AUTOSAR XML (schema 4-0-3)
package /ComponentTypes
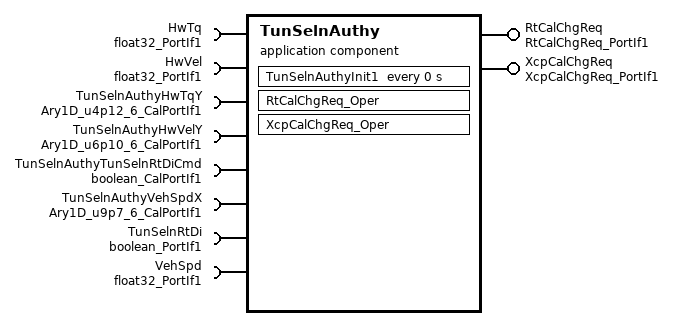
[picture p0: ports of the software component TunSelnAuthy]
  application sw component type TunSelnAuthy
    provide port RtCalChgReq: server-com-spec{operation=Oper, queue-length=1}, provided-interface=RtCalChgReq_PortIf1
    provide port XcpCalChgReq: server-com-spec{operation=Oper, queue-length=1}, provided-interface=XcpCalChgReq_PortIf1
    8 x require port:
      HwTq: nonqueued-receiver-com-spec{data-element=Val, filter=data-filter-type=ALWAYS, init-value=0}, required-interface=float32_PortIf1
      HwVel: nonqueued-receiver-com-spec{data-element=Val, filter=data-filter-type=ALWAYS, init-value=0}, required-interface=float32_PortIf1
      TunSelnAuthyHwTqY: parameter-require-com-spec{init-value=6 x 20480, parameter=Ary1D}, required-interface=Ary1D_u4p12_6_CalPortIf1
      TunSelnAuthyHwVelY: parameter-require-com-spec{init-value=6 x 20480, parameter=Ary1D}, required-interface=Ary1D_u6p10_6_CalPortIf1
      TunSelnAuthyTunSelnRtDiCmd: parameter-require-com-spec{init-value=0, parameter=Logl}, required-interface=boolean_CalPortIf1
      TunSelnAuthyVehSpdX: parameter-require-com-spec{init-value=[0, 12800, 25600, 38400, 51200, 65408], parameter=Ary1D}, required-interface=Ary1D_u9p7_6_CalPortIf1
      TunSelnRtDi: nonqueued-receiver-com-spec{data-element=Logl, filter=data-filter-type=ALWAYS, init-value=0}, required-interface=boolean_PortIf1
      VehSpd: nonqueued-receiver-com-spec{data-element=Val, filter=data-filter-type=ALWAYS, init-value=0}, required-interface=float32_PortIf1
    behavior TunSelnAuthy_InternalBehavior
      operation invoked event OIT_RtCalChgReq_Oper_RtCalChgReq_Oper: start-on-event=RtCalChgReq_Oper, operation=RtCalChgReq.Oper
      timing event TunSelnAuthy_InitEvent: start-on-event=TunSelnAuthyInit1, period=0
      operation invoked event OIT_XcpCalChgReq_Oper_XcpCalChgReq_Oper: start-on-event=XcpCalChgReq_Oper, operation=XcpCalChgReq.Oper
      runnable RtCalChgReq_Oper
        data-receive-point-by-arguments:
          4 x access:
            REC_HwTq_Val: accessed-variable=HwTq.Val
            REC_HwVel_Val: accessed-variable=HwVel.Val
            REC_TunSelnRtDi_Logl: accessed-variable=TunSelnRtDi.Logl
            REC_VehSpd_Val: accessed-variable=VehSpd.Val
      runnable TunSelnAuthyInit1
      runnable XcpCalChgReq_Oper
        data-receive-point-by-arguments:
          access REC_VehSpd_Val: accessed-variable=VehSpd.Val
  swc implementation TunSelnAuthy_Implementation: behavior=TunSelnAuthy_InternalBehavior
    code-descriptors:
      code Default: artifact-descriptors=autosar-engineering-object={short-label=Default, category=SWSRC}
